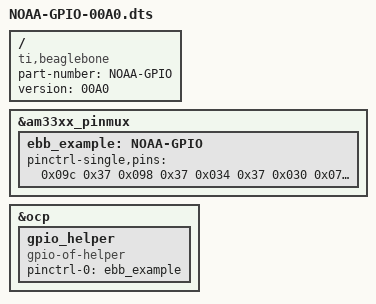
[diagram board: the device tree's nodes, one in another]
/*
 * This defines the GPOI for the POPS instrument.
 * P8.9, P8.10, P8.11  Input (P8.11 pulled up to read a shutdown)
 * P8.12, P8.13, P8.14 Output (P8.14 pulled up)
 */

/dts-v1/;
/plugin/;

/{
       compatible = "ti,beaglebone", "ti,beaglebone-black";
       part-number = "NOAA-GPIO";
       version = "00A0";


       fragment@0 {
             target = <&am33xx_pinmux>;
            
             __overlay__ {
                  ebb_example: NOAA-GPIO {
			pinctrl-single,pins = <
                0x09c 0x37  // P8_9  MODE7 | INPUT  | GPIO pull-up
                0x098 0x37  // P8_10 MODE7 | INPUT  | GPIO pull-up
                0x034 0x37  // P8_11 MODE7 | INPUT  | GPIO pull-up
                0x030 0x07  // P8_12 MODE7 | OUTPUT | GPIO pull-down
                0x024 0x07  // P8_13 MODE7 | OUTPUT | GPIO pull-down
                0x028 0x07  // P8_14 MODE7 | OUTPUT | GPIO pull-down
			>;
		  };
             };
       };

       fragment@1 {
		target = <&ocp>;
		__overlay__ {
			gpio_helper {
				compatible = "gpio-of-helper";
				status = "okay";
				pinctrl-names = "default";
				pinctrl-0 = <&ebb_example>;
			};
		};
	};
};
